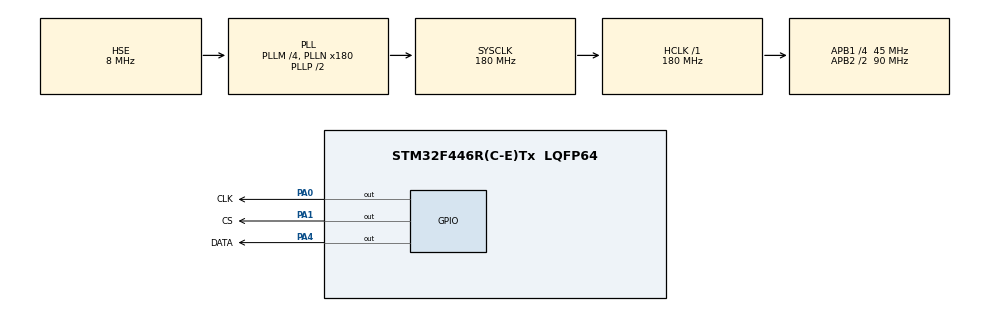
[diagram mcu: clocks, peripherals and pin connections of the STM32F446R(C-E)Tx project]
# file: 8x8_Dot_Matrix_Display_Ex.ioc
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Mcu.Family=STM32F4
Mcu.Name=STM32F446R(C-E)Tx
Mcu.Package=LQFP64
NVIC.PriorityGroup=NVIC_PRIORITYGROUP_4
PA0-WKUP.GPIO_Label=CLK
PA0-WKUP.Signal=GPIO_Output
PA1.GPIO_Label=CS
PA1.Signal=GPIO_Output
PA4.GPIO_Label=DATA
PA4.Signal=GPIO_Output
PH0-OSC_IN.Mode=HSE-External-Oscillator
PH0-OSC_IN.Signal=RCC_OSC_IN
PH1-OSC_OUT.Mode=HSE-External-Oscillator
PH1-OSC_OUT.Signal=RCC_OSC_OUT
ProjectManager.HeapSize=0x200
ProjectManager.StackSize=0x400
ProjectManager.TargetToolchain=STM32CubeIDE
RCC.AHBFreq_Value=180000000
RCC.APB1CLKDivider=RCC_HCLK_DIV4
RCC.APB1Freq_Value=45000000
RCC.APB1TimFreq_Value=90000000
RCC.APB2CLKDivider=RCC_HCLK_DIV2
RCC.APB2Freq_Value=90000000
RCC.APB2TimFreq_Value=180000000
RCC.CortexFreq_Value=180000000
RCC.HCLKFreq_Value=180000000
RCC.HSE_VALUE=8000000
RCC.PLLM=4
RCC.PLLN=180
RCC.PLLSourceVirtual=RCC_PLLSOURCE_HSE
RCC.SYSCLKFreq_VALUE=180000000
RCC.SYSCLKSource=RCC_SYSCLKSOURCE_PLLCLK
RCC.USBFreq_Value=180000000
RCC.VCOOutputFreq_Value=360000000
board=custom

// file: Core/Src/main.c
/* USER CODE BEGIN Header */
/**
  ******************************************************************************
  * @file           : main.c
  * @brief          : Main program body
  ******************************************************************************
  * @attention
  *
  * <h2><center>&copy; Copyright (c) 2020 STMicroelectronics.
  * All rights reserved.</center></h2>
  *
  * This software component is licensed by ST under BSD 3-Clause license,
  * the "License"; You may not use this file except in compliance with the
  * License. You may obtain a copy of the License at:
  *                        opensource.org/licenses/BSD-3-Clause
  *
  ******************************************************************************
  */
/* USER CODE END Header */
#include "main.h"

/* USER CODE BEGIN PV */
uint8_t display[38][8]={
{0x3C,0x42,0x42,0x42,0x42,0x42,0x42,0x3C},//0
{0x10,0x30,0x50,0x10,0x10,0x10,0x10,0x7c},//1
{0x7E,0x2,0x2,0x7E,0x40,0x40,0x40,0x7E},//2
{0x3E,0x2,0x2,0x3E,0x2,0x2,0x3E,0x0},//3
{0x8,0x18,0x28,0x48,0xFE,0x8,0x8,0x8},//4
{0x3C,0x20,0x20,0x3C,0x4,0x4,0x3C,0x0},//5
{0x3C,0x20,0x20,0x3C,0x24,0x24,0x3C,0x0},//6
{0x3E,0x22,0x4,0x8,0x8,0x8,0x8,0x8},//7
{0x0,0x3E,0x22,0x22,0x3E,0x22,0x22,0x3E},//8
{0x3E,0x22,0x22,0x3E,0x2,0x2,0x2,0x3E},//9
{0x18,0x24,0x42,0x42,0x7E,0x42,0x42,0x42},//A
{0x3C,0x22,0x22,0x3c,0x22,0x22,0x3C,0x0},//B
{0x3C,0x40,0x40,0x40,0x40,0x40,0x40,0x3C},//C
{0x7C,0x22,0x22,0x22,0x22,0x22,0x22,0x7C},//D
{0x7C,0x40,0x40,0x7C,0x40,0x40,0x40,0x7C},//E
{0x7C,0x40,0x40,0x7C,0x40,0x40,0x40,0x40},//F
{0x3C,0x40,0x40,0x40,0x4c,0x44,0x44,0x3C},//G
{0x44,0x44,0x44,0x7C,0x44,0x44,0x44,0x44},//H
{0x7C,0x10,0x10,0x10,0x10,0x10,0x10,0x7C},//I
{0x3C,0x8,0x8,0x8,0x8,0x8,0x48,0x30},//J
{0x0,0x24,0x28,0x30,0x20,0x30,0x28,0x24},//K
{0x40,0x40,0x40,0x40,0x40,0x40,0x40,0x7C},//L
{0x81,0xC3,0xA5,0x99,0x81,0x81,0x81,0x81},//M
{0x0,0x42,0x62,0x52,0x4A,0x46,0x42,0x0},//N
{0x3C,0x42,0x42,0x42,0x42,0x42,0x42,0x3C},//O
{0x3C,0x22,0x22,0x22,0x3C,0x20,0x20,0x20},//P
{0x1C,0x22,0x22,0x22,0x22,0x26,0x22,0x1D},//Q
{0x3C,0x22,0x22,0x22,0x3C,0x24,0x22,0x21},//R
{0x0,0x1E,0x20,0x20,0x3E,0x2,0x2,0x3C},//S
{0x0,0x3E,0x8,0x8,0x8,0x8,0x8,0x8},//T
{0x42,0x42,0x42,0x42,0x42,0x42,0x22,0x1C},//U
{0x42,0x42,0x42,0x42,0x42,0x42,0x24,0x18},//V
{0x0,0x49,0x49,0x49,0x49,0x2A,0x1C,0x0},//W
{0x0,0x41,0x22,0x14,0x8,0x14,0x22,0x41},//X
{0x41,0x22,0x14,0x8,0x8,0x8,0x8,0x8},//Y
{0x0,0x7F,0x2,0x4,0x8,0x10,0x20,0x7F},//Z
};

/* USER CODE END PV */

void SystemClock_Config(void);
static void MX_GPIO_Init(void);

/* USER CODE BEGIN 0 */

void WriteByte(uint8_t Byte){

	for ( uint8_t i = 0;  i < 8; i++) {

		HAL_GPIO_WritePin(CLK_GPIO_Port, CLK_Pin, GPIO_PIN_RESET);	//	set the clk pin to low
		HAL_GPIO_WritePin(DATA_GPIO_Port, DATA_Pin, (Byte) & 0x80);	//	get only MSB in data pin
		Byte<<=1;	//	shift left
		HAL_GPIO_WritePin(CLK_GPIO_Port, CLK_Pin, GPIO_PIN_SET);	//	set the clk pin high
	}

}

void WriteByteMax7219(uint8_t Adress , uint8_t Data){

	HAL_GPIO_WritePin(CS_GPIO_Port, CS_Pin, GPIO_PIN_RESET);	//	set the cs pin to low
	WriteByte(Adress);
	WriteByte(Data);
	HAL_GPIO_WritePin(CS_GPIO_Port, CS_Pin, GPIO_PIN_SET);	//	set the cs pin to high

}

void Max7219Init(void){

	WriteByteMax7219(0x09, 0x00);		//	Decode mode0
	WriteByteMax7219(0x0A, 0x0F);		//	Max brightness
	WriteByteMax7219(0x0B, 0x07);		//	Scan limit 8 digits
	WriteByteMax7219(0x0C, 0x01);		//	Normal operation
	WriteByteMax7219(0x0F, 0x00);		//	No test display

}

void WriteData(char* data){

	while(*data){

		for(uint8_t i=1; i<9; i++){
			WriteByteMax7219(i, display[(*data-55)][i-1]);
		}
		*data++;
		HAL_Delay(500);
	}

}

/* USER CODE END 0 */

int main(void)
{

  /* MCU Configuration--------------------------------------------------------*/

  /* Reset of all peripherals, Initializes the Flash interface and the Systick. */
  HAL_Init();

  /* Configure the system clock */
  SystemClock_Config();

  /* Initialize all configured peripherals */
  MX_GPIO_Init();
  /* USER CODE BEGIN 2 */
  Max7219Init();
  /* USER CODE END 2 */

  /* Infinite loop */
  /* USER CODE BEGIN WHILE */
  while (1)
  {
	  WriteData("FENERBAHCE");
	  HAL_Delay(1000);
    /* USER CODE END WHILE */

  }
}

void SystemClock_Config(void)
{
  RCC_OscInitTypeDef RCC_OscInitStruct = {0};
  RCC_ClkInitTypeDef RCC_ClkInitStruct = {0};

  /** Configure the main internal regulator output voltage
  */
  __HAL_RCC_PWR_CLK_ENABLE();
  __HAL_PWR_VOLTAGESCALING_CONFIG(PWR_REGULATOR_VOLTAGE_SCALE1);
  /** Initializes the RCC Oscillators according to the specified parameters
  * in the RCC_OscInitTypeDef structure.
  */
  RCC_OscInitStruct.OscillatorType = RCC_OSCILLATORTYPE_HSE;
  RCC_OscInitStruct.HSEState = RCC_HSE_ON;
  RCC_OscInitStruct.PLL.PLLState = RCC_PLL_ON;
  RCC_OscInitStruct.PLL.PLLSource = RCC_PLLSOURCE_HSE;
  RCC_OscInitStruct.PLL.PLLM = 4;
  RCC_OscInitStruct.PLL.PLLN = 180;
  RCC_OscInitStruct.PLL.PLLP = RCC_PLLP_DIV2;
  RCC_OscInitStruct.PLL.PLLQ = 2;
  RCC_OscInitStruct.PLL.PLLR = 2;
  if (HAL_RCC_OscConfig(&RCC_OscInitStruct) != HAL_OK)
  {
    Error_Handler();
  }
  /** Activate the Over-Drive mode
  */
  if (HAL_PWREx_EnableOverDrive() != HAL_OK)
  {
    Error_Handler();
  }
  /** Initializes the CPU, AHB and APB buses clocks
  */
  RCC_ClkInitStruct.ClockType = RCC_CLOCKTYPE_HCLK|RCC_CLOCKTYPE_SYSCLK
                              |RCC_CLOCKTYPE_PCLK1|RCC_CLOCKTYPE_PCLK2;
  RCC_ClkInitStruct.SYSCLKSource = RCC_SYSCLKSOURCE_PLLCLK;
  RCC_ClkInitStruct.AHBCLKDivider = RCC_SYSCLK_DIV1;
  RCC_ClkInitStruct.APB1CLKDivider = RCC_HCLK_DIV4;
  RCC_ClkInitStruct.APB2CLKDivider = RCC_HCLK_DIV2;

  if (HAL_RCC_ClockConfig(&RCC_ClkInitStruct, FLASH_LATENCY_5) != HAL_OK)
  {
    Error_Handler();
  }
}

static void MX_GPIO_Init(void)
{
  GPIO_InitTypeDef GPIO_InitStruct = {0};

  /* GPIO Ports Clock Enable */
  __HAL_RCC_GPIOH_CLK_ENABLE();
  __HAL_RCC_GPIOA_CLK_ENABLE();

  /*Configure GPIO pin Output Level */
  HAL_GPIO_WritePin(GPIOA, CLK_Pin|CS_Pin|DATA_Pin, GPIO_PIN_RESET);

  /*Configure GPIO pins : CLK_Pin CS_Pin DATA_Pin */
  GPIO_InitStruct.Pin = CLK_Pin|CS_Pin|DATA_Pin;
  GPIO_InitStruct.Mode = GPIO_MODE_OUTPUT_PP;
  GPIO_InitStruct.Pull = GPIO_NOPULL;
  GPIO_InitStruct.Speed = GPIO_SPEED_FREQ_LOW;
  HAL_GPIO_Init(GPIOA, &GPIO_InitStruct);

}

void Error_Handler(void)
{
}

/************************ (C) COPYRIGHT STMicroelectronics *****END OF FILE****/
